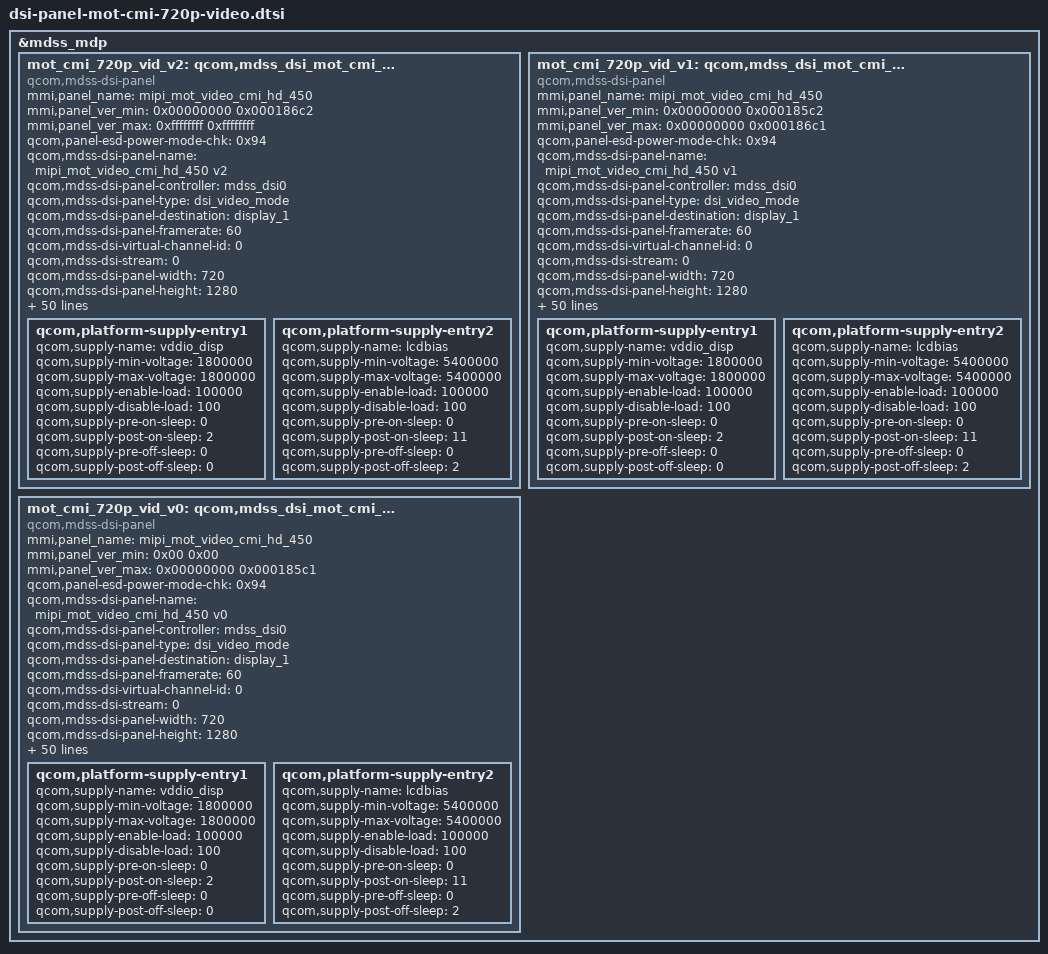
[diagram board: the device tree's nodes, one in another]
/* Copyright (c) 2013, Motorola Mobility LLC. All rights reserved.
 *
 * This program is free software; you can redistribute it and/or modify
 * it under the terms of the GNU General Public License version 2 and
 * only version 2 as published by the Free Software Foundation.
 *
 * This program is distributed in the hope that it will be useful,
 * but WITHOUT ANY WARRANTY; without even the implied warranty of
 * MERCHANTABILITY or FITNESS FOR A PARTICULAR PURPOSE.  See the
 * GNU General Public License for more details.
 */

&mdss_mdp {
	mot_cmi_720p_vid_v2: qcom,mdss_dsi_mot_cmi_720p_video_v2 {
                compatible = "qcom,mdss-dsi-panel";
                status = "ok";

                mmi,panel_name = "mipi_mot_video_cmi_hd_450";
                mmi,panel_ver_min = <0x00000000 0x000186c2>;
                mmi,panel_ver_max = <0xffffffff 0xffffffff>;
                qcom,panel-esd-power-mode-chk = <0x94>;

                qcom,mdss-dsi-panel-name = "mipi_mot_video_cmi_hd_450 v2";
                qcom,mdss-dsi-panel-controller = <&mdss_dsi0>;
                qcom,mdss-dsi-panel-type = "dsi_video_mode";
                qcom,mdss-dsi-panel-destination = "display_1";
                qcom,mdss-dsi-panel-framerate = <60>;
                qcom,mdss-dsi-virtual-channel-id = <0>;
                qcom,mdss-dsi-stream = <0>;
                qcom,mdss-dsi-panel-width = <720>;
                qcom,mdss-dsi-panel-height = <1280>;
                qcom,mdss-pan-physical-width-dimension = <56>;
                qcom,mdss-pan-physical-height-dimension = <99>;
                qcom,mdss-dsi-panel-clockrate = <797600000>;
                qcom,mdss-dsi-h-front-porch = <64>;
                qcom,mdss-dsi-h-back-porch = <64>;
                qcom,mdss-dsi-h-pulse-width = <8>;
                qcom,mdss-dsi-h-sync-skew = <0>;
                qcom,mdss-dsi-v-back-porch = <7>;
                qcom,mdss-dsi-v-front-porch = <6>;
                qcom,mdss-dsi-v-pulse-width = <1>;
                qcom,mdss-dsi-h-left-border = <0>;
                qcom,mdss-dsi-h-right-border = <0>;
                qcom,mdss-dsi-v-top-border = <0>;
                qcom,mdss-dsi-v-bottom-border = <0>;
                qcom,mdss-dsi-bpp = <24>;
                qcom,mdss-dsi-underflow-color = <0xff>;
                qcom,mdss-dsi-border-color = <0>;
		qcom,splash-no-solid-fill;

                qcom,mdss-dsi-tune-h-front-porch = <62>;
                qcom,mdss-dsi-tune-h-back-porch = <62>;
                qcom,mdss-dsi-tune-h-pulse-width = <8>;
                qcom,mdss-dsi-tune-v-back-porch = <15>;
                qcom,mdss-dsi-tune-v-front-porch = <15>;
                qcom,mdss-dsi-tune-v-pulse-width = <1280>;

		qcom,mdss-dsi-on-command = [
			29 01 00 00 00 00 02 ff 01
			29 01 00 00 00 00 02 4c 00
			29 01 00 00 00 00 02 fb 01
			29 01 00 00 00 00 02 ff 00
			29 01 00 00 00 00 04 3b 03 04 03
			29 01 00 00 00 00 02 fb 01
			29 01 00 00 78 00 02 11 00      /* exit sleep */
			29 01 00 00 00 00 02 51 ff      /* led_pwm1 */
			29 01 00 00 00 00 02 53 2c      /* led_pwm2 */
			29 01 00 00 00 00 02 35 00      /* turn on tearing sig */
			29 01 00 00 00 00 02 55 92      /* led_pwm3 */
			29 01 00 00 00 00 02 29 00];    /* display on */

		qcom,mdss-dsi-off-command = [
			05 01 00 00 78 00 02 28 00     /* display off */
			05 01 00 00 32 00 02 10 00];   /* enter sleep */

		qcom,mdss-dsi-on-command-state = "dsi_lp_mode";
		qcom,mdss-dsi-off-command-state = "dsi_hs_mode";
		qcom,mdss-dsi-h-sync-pulse = <1>;
		qcom,mdss-dsi-traffic-mode = "non_burst_sync_event";
		qcom,mdss-dsi-bllp-eof-power-mode;
		qcom,mdss-dsi-bllp-power-mode;
		qcom,mdss-dsi-lane-0-state;
		qcom,mdss-dsi-lane-1-state;
		qcom,mdss-dsi-panel-timings = [c3 3e 34 00 55 4f 33 40 29 03 04 00];
		qcom,mdss-dsi-t-clk-post = <0x1e>;
		qcom,mdss-dsi-t-clk-pre = <0x32>;
		qcom,mdss-dsi-bl-min-level = <1>;
		qcom,mdss-dsi-bl-max-level = <4095>;
		qcom,mdss-dsi-dma-trigger = "trigger_sw";
		qcom,mdss-dsi-mdp-trigger = "none";
		qcom,mdss-dsi-bl-pmic-control-type = "bl_ctrl_wled";

		qcom,mdss-dsi-esd-det-mode = <1>;

		qcom,panel-en-reset-sequence = <1 11>;
		qcom,panel-dis-reset-sequence = <0 3>;
		qcom,platform-supply-entry1 {
			qcom,supply-name = "vddio_disp";
			qcom,supply-min-voltage = <1800000>;
			qcom,supply-max-voltage = <1800000>;
			qcom,supply-enable-load = <100000>;
			qcom,supply-disable-load = <100>;
			qcom,supply-pre-on-sleep = <0>;
			qcom,supply-post-on-sleep = <2>;
			qcom,supply-pre-off-sleep = <0>;
			qcom,supply-post-off-sleep = <0>;
		};
		qcom,platform-supply-entry2 {
			qcom,supply-name = "lcdbias";
			qcom,supply-min-voltage = <5400000>;
			qcom,supply-max-voltage = <5400000>;
			qcom,supply-enable-load = <100000>;
			qcom,supply-disable-load = <100>;
			qcom,supply-pre-on-sleep = <0>;
			qcom,supply-post-on-sleep = <11>;
			qcom,supply-pre-off-sleep = <0>;
			qcom,supply-post-off-sleep = <2>;
		};
	};

	mot_cmi_720p_vid_v1: qcom,mdss_dsi_mot_cmi_720p_video_v1 {
		compatible = "qcom,mdss-dsi-panel";
		status = "ok";

		mmi,panel_name = "mipi_mot_video_cmi_hd_450";
		mmi,panel_ver_min = <0x00000000 0x000185c2>;
		mmi,panel_ver_max = <0x00000000 0x000186c1>;
		qcom,panel-esd-power-mode-chk = <0x94>;

		qcom,mdss-dsi-panel-name = "mipi_mot_video_cmi_hd_450 v1";
		qcom,mdss-dsi-panel-controller = <&mdss_dsi0>;
		qcom,mdss-dsi-panel-type = "dsi_video_mode";
		qcom,mdss-dsi-panel-destination = "display_1";
		qcom,mdss-dsi-panel-framerate = <60>;
		qcom,mdss-dsi-virtual-channel-id = <0>;
		qcom,mdss-dsi-stream = <0>;
		qcom,mdss-dsi-panel-width = <720>;
		qcom,mdss-dsi-panel-height = <1280>;
		qcom,mdss-pan-physical-width-dimension = <56>;
		qcom,mdss-pan-physical-height-dimension = <99>;
		qcom,mdss-dsi-panel-clockrate = <797600000>;
		qcom,mdss-dsi-h-front-porch = <64>;
		qcom,mdss-dsi-h-back-porch = <64>;
		qcom,mdss-dsi-h-pulse-width = <8>;
		qcom,mdss-dsi-h-sync-skew = <0>;
		qcom,mdss-dsi-v-back-porch = <7>;
		qcom,mdss-dsi-v-front-porch = <6>;
		qcom,mdss-dsi-v-pulse-width = <1>;
		qcom,mdss-dsi-h-left-border = <0>;
		qcom,mdss-dsi-h-right-border = <0>;
		qcom,mdss-dsi-v-top-border = <0>;
		qcom,mdss-dsi-v-bottom-border = <0>;
		qcom,mdss-dsi-bpp = <24>;
		qcom,mdss-dsi-underflow-color = <0xff>;
		qcom,mdss-dsi-border-color = <0>;
		qcom,splash-no-solid-fill;

		qcom,mdss-dsi-tune-h-front-porch = <62>;
		qcom,mdss-dsi-tune-h-back-porch = <62>;
		qcom,mdss-dsi-tune-h-pulse-width = <8>;
		qcom,mdss-dsi-tune-v-back-porch = <15>;
		qcom,mdss-dsi-tune-v-front-porch = <15>;
		qcom,mdss-dsi-tune-v-pulse-width = <1280>;

		qcom,mdss-dsi-on-command = [
			29 01 00 00 00 00 02 ff 03
			29 01 00 00 00 00 02 56 00
			29 01 00 00 00 00 02 00 00
			29 01 00 00 00 00 02 01 04
			29 01 00 00 00 00 02 02 08
			29 01 00 00 00 00 02 03 0c
			29 01 00 00 00 00 02 04 10
			29 01 00 00 00 00 02 05 14
			29 01 00 00 00 00 02 06 18
			29 01 00 00 00 00 02 07 20
			29 01 00 00 00 00 02 08 24
			29 01 00 00 00 00 02 09 28
			29 01 00 00 00 00 02 0a 30
			29 01 00 00 00 00 02 0b 38
			29 01 00 00 00 00 02 0c 38
			29 01 00 00 00 00 02 0d 30
			29 01 00 00 00 00 02 0e 28
			29 01 00 00 00 00 02 0f 20
			29 01 00 00 00 00 02 1b 00
			29 01 00 00 00 00 02 1c 04
			29 01 00 00 00 00 02 1d 08
			29 01 00 00 00 00 02 1e 0c
			29 01 00 00 00 00 02 1f 10
			29 01 00 00 00 00 02 20 14
			29 01 00 00 00 00 02 24 10
			29 01 00 00 00 00 02 25 08
			29 01 00 00 00 00 02 18 28
			29 01 00 00 00 00 02 19 38
			29 01 00 00 00 00 02 1a 77
			29 01 00 00 00 00 02 21 18
			29 01 00 00 00 00 02 22 20
			29 01 00 00 00 00 02 23 18
			29 01 00 00 00 00 02 fb 01
			29 01 00 00 00 00 02 ff 00
			29 01 00 00 00 00 02 ff 01
			29 01 00 00 00 00 02 4c 00
			29 01 00 00 00 00 02 fb 01
			29 01 00 00 00 00 02 ff 00
			29 01 00 00 00 00 04 3b 03 04 03
			29 01 00 00 00 00 02 fb 01
			29 01 00 00 78 00 02 11 00      /* exit sleep */
			29 01 00 00 00 00 02 ff 04
			29 01 00 00 00 00 02 08 04
			29 01 00 00 00 00 02 ff 00
			29 01 00 00 00 00 02 51 ff      /* led_pwm1 */
			29 01 00 00 00 00 02 53 2c      /* led_pwm2 */
			29 01 00 00 00 00 02 35 00      /* turn on tearing sig */
			29 01 00 00 00 00 02 55 92      /* led_pwm3 */
			29 01 00 00 00 00 02 29 00];    /* display on */

		qcom,mdss-dsi-off-command = [
			05 01 00 00 78 00 02 28 00     /* display off */
			05 01 00 00 32 00 02 10 00];   /* enter sleep */

		qcom,mdss-dsi-on-command-state = "dsi_lp_mode";
		qcom,mdss-dsi-off-command-state = "dsi_hs_mode";
		qcom,mdss-dsi-h-sync-pulse = <1>;
		qcom,mdss-dsi-traffic-mode = "non_burst_sync_event";
		qcom,mdss-dsi-bllp-eof-power-mode;
		qcom,mdss-dsi-bllp-power-mode;
		qcom,mdss-dsi-lane-0-state;
		qcom,mdss-dsi-lane-1-state;
		qcom,mdss-dsi-panel-timings = [c3 3e 34 00 55 4f 33 40 29 03 04 00];
		qcom,mdss-dsi-t-clk-post = <0x1e>;
		qcom,mdss-dsi-t-clk-pre = <0x32>;
		qcom,mdss-dsi-bl-min-level = <1>;
		qcom,mdss-dsi-bl-max-level = <4095>;
		qcom,mdss-dsi-dma-trigger = "trigger_sw";
		qcom,mdss-dsi-mdp-trigger = "none";
		qcom,mdss-dsi-bl-pmic-control-type = "bl_ctrl_wled";

		qcom,mdss-dsi-esd-det-mode = <1>;

		qcom,panel-en-reset-sequence = <1 11>;
		qcom,panel-dis-reset-sequence = <0 3>;
		qcom,platform-supply-entry1 {
			qcom,supply-name = "vddio_disp";
			qcom,supply-min-voltage = <1800000>;
			qcom,supply-max-voltage = <1800000>;
			qcom,supply-enable-load = <100000>;
			qcom,supply-disable-load = <100>;
			qcom,supply-pre-on-sleep = <0>;
			qcom,supply-post-on-sleep = <2>;
			qcom,supply-pre-off-sleep = <0>;
			qcom,supply-post-off-sleep = <0>;
		};
		qcom,platform-supply-entry2 {
			qcom,supply-name = "lcdbias";
			qcom,supply-min-voltage = <5400000>;
			qcom,supply-max-voltage = <5400000>;
			qcom,supply-enable-load = <100000>;
			qcom,supply-disable-load = <100>;
			qcom,supply-pre-on-sleep = <0>;
			qcom,supply-post-on-sleep = <11>;
			qcom,supply-pre-off-sleep = <0>;
			qcom,supply-post-off-sleep = <2>;
		};
	};

	mot_cmi_720p_vid_v0: qcom,mdss_dsi_mot_cmi_720p_video_v0 {
		compatible = "qcom,mdss-dsi-panel";
		status = "ok";

		mmi,panel_name = "mipi_mot_video_cmi_hd_450";
		mmi,panel_ver_min = <0x00 0x00>;
		mmi,panel_ver_max = <0x00000000 0x000185c1>;
		qcom,panel-esd-power-mode-chk = <0x94>;

		qcom,mdss-dsi-panel-name = "mipi_mot_video_cmi_hd_450 v0";
		qcom,mdss-dsi-panel-controller = <&mdss_dsi0>;
		qcom,mdss-dsi-panel-type = "dsi_video_mode";
		qcom,mdss-dsi-panel-destination = "display_1";
		qcom,mdss-dsi-panel-framerate = <60>;
		qcom,mdss-dsi-virtual-channel-id = <0>;
		qcom,mdss-dsi-stream = <0>;
		qcom,mdss-dsi-panel-width = <720>;
		qcom,mdss-dsi-panel-height = <1280>;
		qcom,mdss-pan-physical-width-dimension = <56>;
		qcom,mdss-pan-physical-height-dimension = <99>;
		qcom,mdss-dsi-panel-clockrate = <797600000>;
		qcom,mdss-dsi-h-front-porch = <64>;
		qcom,mdss-dsi-h-back-porch = <64>;
		qcom,mdss-dsi-h-pulse-width = <8>;
		qcom,mdss-dsi-h-sync-skew = <0>;
		qcom,mdss-dsi-v-back-porch = <7>;
		qcom,mdss-dsi-v-front-porch = <6>;
		qcom,mdss-dsi-v-pulse-width = <1>;
		qcom,mdss-dsi-h-left-border = <0>;
		qcom,mdss-dsi-h-right-border = <0>;
		qcom,mdss-dsi-v-top-border = <0>;
		qcom,mdss-dsi-v-bottom-border = <0>;
		qcom,mdss-dsi-bpp = <24>;
		qcom,mdss-dsi-underflow-color = <0xff>;
		qcom,mdss-dsi-border-color = <0>;
		qcom,splash-no-solid-fill;

		qcom,mdss-dsi-tune-h-front-porch = <62>;
		qcom,mdss-dsi-tune-h-back-porch = <62>;
		qcom,mdss-dsi-tune-h-pulse-width = <8>;
		qcom,mdss-dsi-tune-v-back-porch = <15>;
		qcom,mdss-dsi-tune-v-front-porch = <15>;
		qcom,mdss-dsi-tune-v-pulse-width = <1280>;

		qcom,mdss-dsi-on-command = [
			29 01 00 00 00 00 02 ba 01
			29 01 00 00 00 00 02 fb 01
			29 01 00 00 78 00 02 11 00      /* exit sleep */
			29 01 00 00 00 00 02 51 ff      /* led_pwm1 */
			29 01 00 00 00 00 02 53 2c      /* led_pwm2 */
			29 01 00 00 00 00 02 35 00      /* turn on tearing sig */
			29 01 00 00 00 00 02 55 03      /* led_pwm3 */
			29 01 00 00 00 00 02 29 00];    /* display on */

		qcom,mdss-dsi-off-command = [
			05 01 00 00 78 00 02 28 00     /* display off */
			05 01 00 00 32 00 02 10 00];   /* enter sleep */

		qcom,mdss-dsi-on-command-state = "dsi_lp_mode";
		qcom,mdss-dsi-off-command-state = "dsi_hs_mode";
		qcom,mdss-dsi-h-sync-pulse = <1>;
		qcom,mdss-dsi-traffic-mode = "non_burst_sync_event";
		qcom,mdss-dsi-bllp-eof-power-mode;
		qcom,mdss-dsi-bllp-power-mode;
		qcom,mdss-dsi-lane-0-state;
		qcom,mdss-dsi-lane-1-state;
		qcom,mdss-dsi-panel-timings = [c3 3e 34 00 55 4f 33 40 29 03 04 00];
		qcom,mdss-dsi-t-clk-post = <0x1e>;
		qcom,mdss-dsi-t-clk-pre = <0x32>;
		qcom,mdss-dsi-bl-min-level = <1>;
		qcom,mdss-dsi-bl-max-level = <4095>;
		qcom,mdss-dsi-dma-trigger = "trigger_sw";
		qcom,mdss-dsi-mdp-trigger = "none";
		qcom,mdss-dsi-bl-pmic-control-type = "bl_ctrl_wled";

		qcom,mdss-dsi-esd-det-mode = <1>;

		qcom,panel-en-reset-sequence = <1 11>;
		qcom,panel-dis-reset-sequence = <0 3>;
		qcom,platform-supply-entry1 {
			qcom,supply-name = "vddio_disp";
			qcom,supply-min-voltage = <1800000>;
			qcom,supply-max-voltage = <1800000>;
			qcom,supply-enable-load = <100000>;
			qcom,supply-disable-load = <100>;
			qcom,supply-pre-on-sleep = <0>;
			qcom,supply-post-on-sleep = <2>;
			qcom,supply-pre-off-sleep = <0>;
			qcom,supply-post-off-sleep = <0>;
		};
		qcom,platform-supply-entry2 {
			qcom,supply-name = "lcdbias";
			qcom,supply-min-voltage = <5400000>;
			qcom,supply-max-voltage = <5400000>;
			qcom,supply-enable-load = <100000>;
			qcom,supply-disable-load = <100>;
			qcom,supply-pre-on-sleep = <0>;
			qcom,supply-post-on-sleep = <11>;
			qcom,supply-pre-off-sleep = <0>;
			qcom,supply-post-off-sleep = <2>;
		};
	};
};
